# Q32M210 register map
File version: 1.0
Registers are 32-bit, read-write, no defined reset value unless marked. A register's access mark holds for its fields unless they carry their own. Offsets are from the block's base; [hi:lo] are bit positions.

## SPI0_Interface_Configuration_and_Control
Base 0x40000600
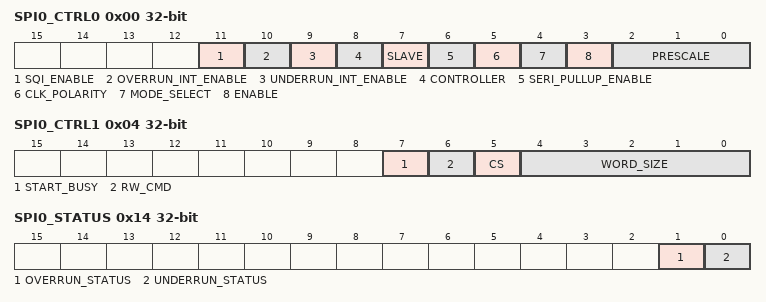
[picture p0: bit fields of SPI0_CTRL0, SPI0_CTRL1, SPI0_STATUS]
0x00 SPI0_CTRL0 — SPI0 Control and Configuration Register
  [11] SQI_ENABLE — Enable SQI operation (nibble width transfers)
    0=SPI0_SELECT_SPI (The SPI0 interface operates in SPI mode); 1=SPI0_SELECT_SQI (The SPI0 interface operates in SQI mode)
  [10] OVERRUN_INT_ENABLE — Enable SPI0 overrun interrupts
    0=SPI0_OVERRUN_INT_DISABLE (No interrupts are raised when an overrun occurs on the SPI0 interface); 1=SPI0_OVERRUN_INT_ENABLE (An interrupt is raised when an overrun occurs on the SPI0 interface)
  [9] UNDERRUN_INT_ENABLE — Enable SPI0 underrun interrupts
    0=SPI0_UNDERRUN_INT_DISABLE (No interrupts are raised when an underrun occurs on the SPI0 interface); 1=SPI0_UNDERRUN_INT_ENABLE (An interrupt is raised when an underrun occurs on the SPI0 interface)
  [8] CONTROLLER — Select whether data transfer will be controlled by the ARM Cortex-M3 processor or the DMA for SPI0
    0=SPI0_CONTROLLER_CM3 (The ARM Cortex-M3 controls data transfers using SPI0); 1=SPI0_CONTROLLER_DMA (The DMA controls data transfers using SPI0)
  [7] SLAVE — Use the SPI0 interface as master or slave
    0=SPI0_SELECT_MASTER (Use the SPI0 interface in master mode); 1=SPI0_SELECT_SLAVE (Use the SPI0 interface in slave mode)
  [6] SERI_PULLUP_ENABLE — Configure the optional pull-up resistor for the SERI pad of SPI0
    0=SPI0_SERI_PULLUP_DISABLE (Disconnect the pull-up resistor from the SPI0 SERI pad); 1=SPI0_SERI_PULLUP_ENABLE (Connect a pull-up resistor to the SPI0 SERI pad)
  [5] CLK_POLARITY — Select the polarity of the SPI0 clock
    0=SPI0_CLK_POLARITY_NORMAL (SERO changes on the rising edge of SPI0 clock, SERI changes on the falling edge of SPI0 clock); 1=SPI0_CLK_POLARITY_INVERSE (SERO changes on the falling edge of SPI0 clock, SERI changes on the rising edge of SPI0 clock)
  [4] MODE_SELECT — Select between manual and auto transaction handling modes for SPI0 master transactions
    0=SPI0_MODE_SELECT_MANUAL (Master transfers using the SPI0 interface do not automatically continue); 1=SPI0_MODE_SELECT_AUTO (Automatically continue master transfers using the SPI0 interface)
  [3] ENABLE — Enable/disable the SPI0 interface
    0=SPI0_DISABLE (Disable the SPI0 interface); 1=SPI0_ENABLE (Enable the SPI0 interface)
  [2:0] PRESCALE — Prescale the SPI0 interface clock for master transfers
    0=SPI0_PRESCALE_2 (Prescale the SPI0 interface clock by 2); 1=SPI0_PRESCALE_4 (Prescale the SPI0 interface clock by 4); 2=SPI0_PRESCALE_8 (Prescale the SPI0 interface clock by 8); 3=SPI0_PRESCALE_16 (Prescale the SPI0 interface clock by 16); 4=SPI0_PRESCALE_32 (Prescale the SPI0 interface clock by 32); 5=SPI0_PRESCALE_64 (Prescale the SPI0 interface clock by 64); 6=SPI0_PRESCALE_128 (Prescale the SPI0 interface clock by 128); 7=SPI0_PRESCALE_256 (Prescale the SPI0 interface clock by 256)
0x04 SPI0_CTRL1 — SPI0 Transaction Control Register
  [7] START_BUSY — Start an SPI0 data transfer and indicate if a transfer is in progress
    0=SPI0_IDLE (Stop a transfer or indicate that the SPI0 interface is idle); 1=SPI0_START (Start a transfer on the SPI0 interface); 1=SPI0_BUSY (Indicate that the SPI0 interface is currently transferring data)
  [6] RW_CMD — Issue a read command or write command to the SPI0 interface
    0=SPI0_WRITE_DATA (Write data using the SPI0 interface); 1=SPI0_READ_DATA (Read data using the SPI0 interface)
  [5] CS — Set the chip-select line for SPI0 (master mode); read the chip-select line for SPI0 (slave mode)
    0=SPI0_CS_0 (Set the chip-select line to 0); 1=SPI0_CS_1 (Set the chip-select line to 1)
  [4:0] WORD_SIZE — Select the word size used by the SPI interface (word size = SPI0_CTRL1_WORD_SIZE + 1)
    0=SPI0_WORD_SIZE_1 (SPI transfers use 1-bit words); 7=SPI0_WORD_SIZE_8 (SPI transfers use 8-bit words); 15=SPI0_WORD_SIZE_16 (SPI transfers use 16-bit words); 23=SPI0_WORD_SIZE_24 (SPI transfers use 24-bit words); 31=SPI0_WORD_SIZE_32 (SPI transfers use 32-bit words)
0x08 SPI0_DATA
  [31:0] SPI0_DATA — Single word buffer for data to be transmitted over the SPI0 interface and data that has been received over the SPI0 interface
0x0C SPI0_DATA_S — Shadow of SPI0 Data
  [31:0] SPI0_DATA_S — "Shadow register for SPI0_DATA providing no side effect access to the interface's data"
0x10 SPI0_SLAVE_DATA — SPI0 Data for Slave Operations
  [31:0] SPI0_DATA — Single word buffer for data that has been received over the SPI0 interface when operating in slave mode
0x14 SPI0_STATUS
  [1] OVERRUN_STATUS — Indicate that an overrun has occurred when receiving data on the SPI0 interface
    0=SPI0_OVERRUN_FALSE (SPI0 no input overrun detected); 1=SPI0_OVERRUN_TRUE (SPI0 input overrun detected); 1=SPI0_OVERRUN_CLEAR (Clear the SPI0 overrun bit)
  [0] UNDERRUN_STATUS — Indicate that an underrun has occurred when transmitting data on the SPI0 interface
    0=SPI0_UNDERRUN_FALSE (SPI0 no input underrun detected); 1=SPI0_UNDERRUN_TRUE (SPI0 input underrun detected); 1=SPI0_UNDERRUN_CLEAR (Clear the SPI0 underrun bit)
